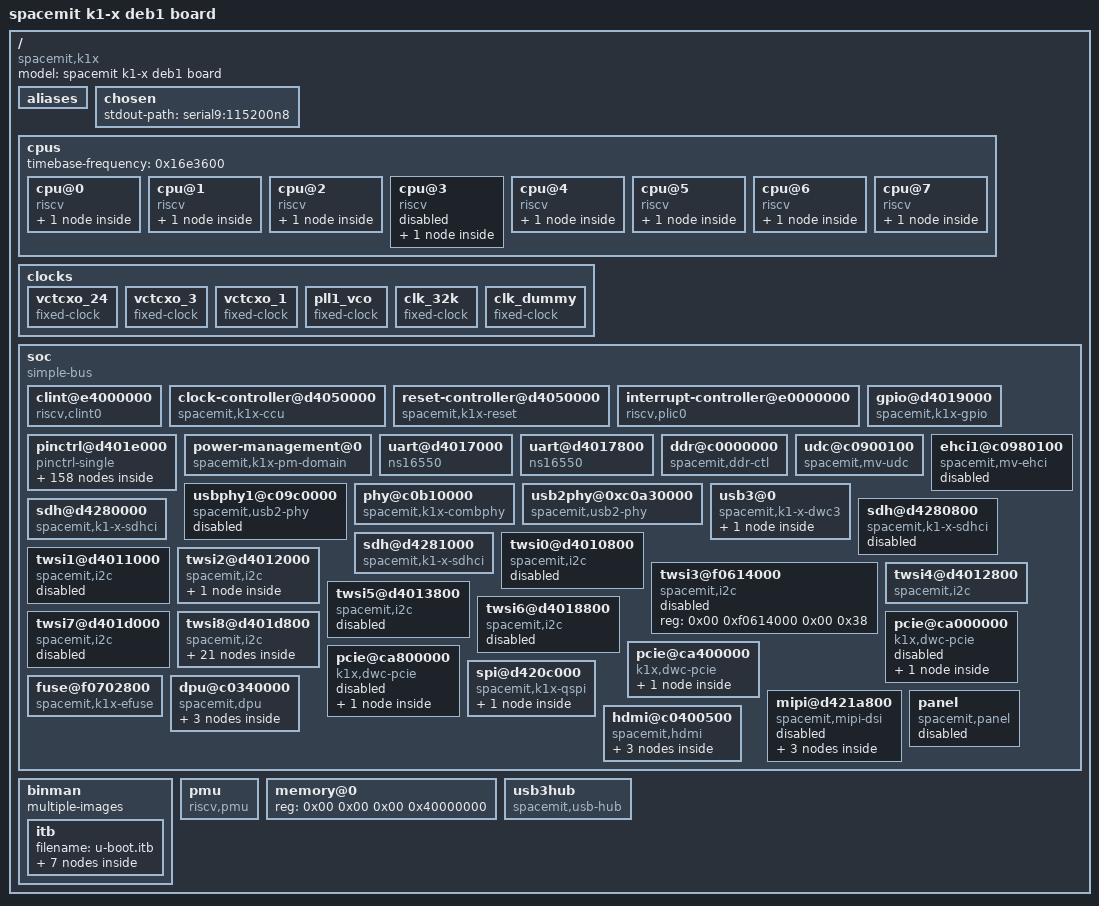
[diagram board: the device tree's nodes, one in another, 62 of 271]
/dts-v1/;

/ {
	compatible = "spacemit,k1x\0riscv";
	#address-cells = <0x02>;
	#size-cells = <0x02>;
	model = "spacemit k1-x deb1 board";

	aliases {
		serial0 = "/soc/uart@d4017000";
		serial9 = "/soc/uart@d4017800";
		mmc0 = "/soc/sdh@d4280000";
		mmc1 = "/soc/sdh@d4280800";
		mmc2 = "/soc/sdh@d4281000";
		efuse_power = "/soc/twsi8@d401d800/pmic@41/regulators/LDO_REG9";
	};

	chosen {
		stdout-path = "serial9:115200n8";
/*
		bootargs = "earlycon=sbi console=ttyS0,115200 debug loglevel=8,initcall_debug=1 rdinit=/init.tmp";
		stdout-path = "serial9:115200n8";

		opensbi-domains {
			compatible = "opensbi,domain,config";

			rpmsg_shmem {
				compatible = "opensbi,domain,memregion";
				base = <0x00 0x4e400000>;
				order = <0x16>;
				phandle = <0x02>;
			};

			rtcode {
				compatible = "opensbi,domain,memregion";
				base = <0x00 0x4e800000>;
				order = <0x17>;
				phandle = <0x03>;
			};

			rtheap {
				compatible = "opensbi,domain,memregion";
				base = <0x00 0x4f000000>;
				order = <0x18>;
				phandle = <0x04>;
			};

			allmem {
				compatible = "opensbi,domain,memregion";
				base = <0x00 0x00>;
				order = <0x40>;
				phandle = <0x05>;
			};

			t-domain {
				compatible = "opensbi,domain,instance";
				possible-harts = <0x01>;
				regions = <0x02 0x3f 0x03 0x3f 0x04 0x3f 0x05 0x3f>;
				boot-hart = <0x01>;
				next-arg1 = <0x00 0x42200000>;
				next-addr = <0x00 0x4e800000>;
				next-mode = <0x01>;
				phandle = <0x0e>;
			};

			u-domain {
				compatible = "opensbi,domain,instance";
				possible-harts = <0x06 0x07 0x08 0x09 0x0a 0x0b 0x0c>;
				regions = <0x02 0x3f 0x03 0x3f 0x04 0x3f 0x05 0x3f>;
				next-addr = <0x00 0x200000>;
				next-arg1 = <0x00 0x31b180>;
				boot-hart = <0x07>;
				system-reset-allowed;
				system-suspend-allowed;
				phandle = <0x0d>;
			};
		};
*/
	};

	cpus {
		#address-cells = <0x01>;
		#size-cells = <0x00>;
		timebase-frequency = <0x16e3600>;

		cpu@0 {
			compatible = "riscv";
			device_type = "cpu";
			reg = <0x00>;
			status = "okay";
			riscv,isa = "rv64imafdcvsu_zicsr_zifencei_zicbom_zihintpause_zba_zbb_zbc_zbs_svpbmt_sstc_sscofpmf";
			mmu-type = "riscv,sv39";
			opensbi-domain = <0x0d>;
			boot_freq_cluster0 = <0x12bce0>;
			boot_freq_cluster1 = <0x12bce0>;
			phandle = <0x06>;

			interrupt-controller {
				#interrupt-cells = <0x01>;
				compatible = "riscv,cpu-intc";
				interrupt-controller;
				phandle = <0x0f>;
			};
		};

		cpu@1 {
			compatible = "riscv";
			device_type = "cpu";
			reg = <0x01>;
			status = "okay";
			riscv,isa = "rv64imafdcvsu_zicsr_zifencei_zicbom_zihintpause_zba_zbb_zbc_zbs_svpbmt_sstc_sscofpmf";
			mmu-type = "riscv,sv39";
			opensbi-domain = <0x0d>;
			phandle = <0x07>;

			interrupt-controller {
				#interrupt-cells = <0x01>;
				compatible = "riscv,cpu-intc";
				interrupt-controller;
				phandle = <0x10>;
			};
		};

		cpu@2 {
			compatible = "riscv";
			device_type = "cpu";
			reg = <0x02>;
			status = "okay";
			riscv,isa = "rv64imafdcvsu_zicsr_zifencei_zicbom_zihintpause_zba_zbb_zbc_zbs_svpbmt_sstc_sscofpmf";
			mmu-type = "riscv,sv39";
			opensbi-domain = <0x0d>;
			phandle = <0x08>;

			interrupt-controller {
				#interrupt-cells = <0x01>;
				compatible = "riscv,cpu-intc";
				interrupt-controller;
				phandle = <0x11>;
			};
		};

		cpu@3 {
			compatible = "riscv";
			device_type = "cpu";
			reg = <0x03>;
			status = "disabled";
			riscv,isa = "rv64imafdcvsu_zicsr_zifencei_zicbom_zihintpause_zba_zbb_zbc_zbs_svpbmt_sstc_sscofpmf";
			mmu-type = "riscv,sv39";
			opensbi-domain = <0x0e>;
			phandle = <0x01>;

			interrupt-controller {
				#interrupt-cells = <0x01>;
				compatible = "riscv,cpu-intc";
				interrupt-controller;
				phandle = <0x12>;
			};
		};

		cpu@4 {
			compatible = "riscv";
			device_type = "cpu";
			reg = <0x04>;
			status = "okay";
			riscv,isa = "rv64imafdcvsu_zicsr_zifencei_zicbom_zihintpause_zba_zbb_zbc_zbs_svpbmt_sstc_sscofpmf";
			mmu-type = "riscv,sv39";
			opensbi-domain = <0x0d>;
			phandle = <0x09>;

			interrupt-controller {
				#interrupt-cells = <0x01>;
				compatible = "riscv,cpu-intc";
				interrupt-controller;
				phandle = <0x13>;
			};
		};

		cpu@5 {
			compatible = "riscv";
			device_type = "cpu";
			reg = <0x05>;
			status = "okay";
			riscv,isa = "rv64imafdcvsu_zicsr_zifencei_zicbom_zihintpause_zba_zbb_zbc_zbs_svpbmt_sstc_sscofpmf";
			mmu-type = "riscv,sv39";
			opensbi-domain = <0x0d>;
			phandle = <0x0a>;

			interrupt-controller {
				#interrupt-cells = <0x01>;
				compatible = "riscv,cpu-intc";
				interrupt-controller;
				phandle = <0x14>;
			};
		};

		cpu@6 {
			compatible = "riscv";
			device_type = "cpu";
			reg = <0x06>;
			status = "okay";
			riscv,isa = "rv64imafdcvsu_zicsr_zifencei_zicbom_zihintpause_zba_zbb_zbc_zbs_svpbmt_sstc_sscofpmf";
			mmu-type = "riscv,sv39";
			opensbi-domain = <0x0d>;
			phandle = <0x0b>;

			interrupt-controller {
				#interrupt-cells = <0x01>;
				compatible = "riscv,cpu-intc";
				interrupt-controller;
				phandle = <0x15>;
			};
		};

		cpu@7 {
			compatible = "riscv";
			device_type = "cpu";
			reg = <0x07>;
			status = "okay";
			riscv,isa = "rv64imafdcvsu_zicsr_zifencei_zicbom_zihintpause_zba_zbb_zbc_zbs_svpbmt_sstc_sscofpmf";
			mmu-type = "riscv,sv39";
			opensbi-domain = <0x0d>;
			phandle = <0x0c>;

			interrupt-controller {
				#interrupt-cells = <0x01>;
				compatible = "riscv,cpu-intc";
				interrupt-controller;
				phandle = <0x16>;
			};
		};
	};

	clocks {
		#address-cells = <0x02>;
		#size-cells = <0x02>;
		ranges;

		vctcxo_24 {
			#clock-cells = <0x00>;
			compatible = "fixed-clock";
			clock-frequency = <0x16e3600>;
			clock-output-names = "vctcxo_24";
			phandle = <0x17>;
		};

		vctcxo_3 {
			#clock-cells = <0x00>;
			compatible = "fixed-clock";
			clock-frequency = <0x2dc6c0>;
			clock-output-names = "vctcxo_3";
			phandle = <0x18>;
		};

		vctcxo_1 {
			#clock-cells = <0x00>;
			compatible = "fixed-clock";
			clock-frequency = <0xf4240>;
			clock-output-names = "vctcxo_1";
			phandle = <0x19>;
		};

		pll1_vco {
			#clock-cells = <0x00>;
			compatible = "fixed-clock";
			clock-frequency = <0x1770000>;
			clock-output-names = "pll1_vco";
			phandle = <0x1a>;
		};

		clk_32k {
			#clock-cells = <0x00>;
			compatible = "fixed-clock";
			clock-frequency = <0x7d00>;
			clock-output-names = "clk_32k";
			phandle = <0x1b>;
		};

		clk_dummy {
			#clock-cells = <0x00>;
			compatible = "fixed-clock";
			clock-frequency = <0x00>;
			clock-output-names = "clk_dummy";
			phandle = <0x1c>;
		};
	};

	soc {
		compatible = "simple-bus";
		#address-cells = <0x02>;
		#size-cells = <0x02>;
		ranges;

		clint@e4000000 {
			compatible = "riscv,clint0";
			interrupts-extended = <0x0f 0x03 0x0f 0x07 0x10 0x03 0x10 0x07 0x11 0x03 0x11 0x07 0x12 0x03 0x12 0x07 0x13 0x03 0x13 0x07 0x14 0x03 0x14 0x07 0x15 0x03 0x15 0x07 0x16 0x03 0x16 0x07>;
			reg = <0x00 0xe4000000 0x00 0x10000>;
		};

		clock-controller@d4050000 {
			compatible = "spacemit,k1x-ccu";
			reg = <0x00 0xd4050000 0x00 0x209c 0x00 0xd4282800 0x00 0x400 0x00 0xd4015000 0x00 0x1000 0x00 0xd4090000 0x00 0x1000 0x00 0xd4282c00 0x00 0x400 0x00 0xd8440000 0x00 0x98 0x00 0xc0000000 0x00 0x4280 0x00 0xf0610000 0x00 0x20>;
			reg-names = "mpmu\0apmu\0apbc\0apbs\0ciu\0dciu\0ddrc\0apbc2";
			clocks = <0x17 0x18 0x19 0x1a 0x1b 0x1c>;
			clock-names = "vctcxo_24\0vctcxo_3\0vctcxo_1\0pll1_vco\0clk_32k\0clk_dummy";
			#clock-cells = <0x01>;
			status = "okay";
			phandle = <0x1d>;
		};

		reset-controller@d4050000 {
			compatible = "spacemit,k1x-reset";
			reg = <0x00 0xd4050000 0x00 0x209c 0x00 0xd4282800 0x00 0x400 0x00 0xd4015000 0x00 0x1000 0x00 0xd4090000 0x00 0x1000 0x00 0xd4282c00 0x00 0x400 0x00 0xd8440000 0x00 0x98 0x00 0xc0000000 0x00 0x4280 0x00 0xf0610000 0x00 0x20>;
			reg-names = "mpmu\0apmu\0apbc\0apbs\0ciu\0dciu\0ddrc\0apbc2";
			#reset-cells = <0x01>;
			status = "okay";
			phandle = <0x21>;
		};

		interrupt-controller@e0000000 {
			#interrupt-cells = <0x01>;
			compatible = "riscv,plic0";
			interrupt-controller;
			interrupts-extended = <0x0f 0x0b 0x0f 0x09 0x10 0x0b 0x10 0x09 0x11 0x0b 0x11 0x09 0x12 0x0b 0x12 0x09 0x13 0x0b 0x13 0x09 0x14 0x0b 0x14 0x09 0x15 0x0b 0x15 0x09 0x16 0x0b 0x16 0x09>;
			reg = <0x00 0xe0000000 0x00 0x4000000>;
			reg-names = "control";
			riscv,max-priority = <0x07>;
			riscv,ndev = <0x9f>;
			phandle = <0x1e>;
		};

		gpio@d4019000 {
			compatible = "spacemit,k1x-gpio";
			reg = <0x00 0xd4019000 0x00 0x800>;
			gpio-controller;
			gpio-count = <0x80>;
			#gpio-cells = <0x02>;
			interrupts = <0x3a>;
			clocks = <0x1d 0x6c>;
			interrupt-names = "gpio_mux";
			interrupt-parent = <0x1e>;
			gpio-ranges = <0x1f 0x31 0x32 0x02 0x1f 0x3a 0x3b 0x01 0x1f 0x3f 0x40 0x05 0x1f 0x46 0x47 0x04 0x1f 0x4a 0x4b 0x01 0x1f 0x50 0x51 0x04 0x1f 0x5a 0x7f 0x03 0x1f 0x60 0x78 0x02 0x1f 0x6e 0x74 0x01 0x1f 0x72 0x86 0x03 0x1f 0x7b 0x8f 0x05>;
			phandle = <0x2a>;
		};

		pinctrl@d401e000 {
			compatible = "pinctrl-single";
			reg = <0x00 0xd401e000 0x00 0x400>;
			#address-cells = <0x01>;
			#size-cells = <0x01>;
			#pinctrl-cells = <0x02>;
			#gpio-range-cells = <0x03>;
			pinctrl-single,register-width = <0x20>;
			pinctrl-single,function-mask = <0xff77>;
			pinctrl-single,gpio-range = <0x20 0x32 0x02 0xc440 0x20 0x3b 0x01 0xb040 0x20 0x40 0x02 0xb040 0x20 0x42 0x01 0xd040 0x20 0x43 0x02 0xb040 0x20 0x47 0x02 0xd041 0x20 0x49 0x01 0xb041 0x20 0x4a 0x01 0xd041 0x20 0x4b 0x01 0xd040 0x20 0x51 0x01 0xc440 0x20 0x52 0x03 0xd040 0x20 0x7f 0x01 0xb040 0x20 0x80 0x02 0xd040 0x20 0x78 0x01 0xb041 0x20 0x79 0x01 0xa041 0x20 0x74 0x01 0xb040 0x20 0x86 0x01 0xb040 0x20 0x87 0x02 0xb040 0x20 0x8f 0x01 0xa040 0x20 0x90 0x01 0xd040 0x20 0x91 0x03 0xb040>;
			phandle = <0x1f>;

			gpio-range {
				#pinctrl-single,gpio-range-cells = <0x03>;
				phandle = <0x20>;
			};

			uart0_0_grp {
				pinctrl-single,pins = <0x1b8 0x03 0xc440 0x1bc 0x03 0xc440>;
			};

			uart0_1_grp {
				pinctrl-single,pins = <0x1c8 0x01 0xc440 0x144 0x03 0xa440>;
			};

			uart0_2_grp {
				pinctrl-single,pins = <0x114 0x02 0xb040 0x118 0x02 0xd040>;
			};

			uart2_grp {
				pinctrl-single,pins = <0x58 0x01 0xb040 0x5c 0x01 0xb040 0x60 0x01 0xb040 0x64 0x01 0xb040>;
			};

			uart3_0_grp {
				pinctrl-single,pins = <0x148 0x02 0xd040 0x14c 0x02 0xd040 0x150 0x02 0xd040 0x154 0x02 0xd040>;
			};

			uart3_1_grp {
				pinctrl-single,pins = <0x4c 0x02 0xd040 0x50 0x02 0xd040 0x54 0x02 0xd040 0x58 0x02 0xb040>;
			};

			uart3_2_grp {
				pinctrl-single,pins = <0xd8 0x04 0xb040 0xdc 0x04 0xd040 0xe0 0x04 0xd040 0xe4 0x04 0xd040>;
			};

			uart4_0_grp {
				pinctrl-single,pins = <0x16c 0x04 0xa440 0x168 0x04 0xa440>;
			};

			uart4_1_grp {
				pinctrl-single,pins = <0x148 0x03 0xd040 0x14c 0x03 0xd040 0x150 0x03 0xd040 0x154 0x03 0xd040>;
			};

			uart4_2_grp {
				pinctrl-single,pins = <0x60 0x02 0xb040 0x64 0x02 0xb040>;
			};

			uart4_3_grp {
				pinctrl-single,pins = <0x88 0x02 0xb040 0x8c 0x02 0xb040 0x90 0x02 0xb040 0x94 0x02 0xb040>;
			};

			uart4_4_grp {
				pinctrl-single,pins = <0x20c 0x04 0xb040 0x210 0x04 0xb040 0x214 0x04 0xb040 0x218 0x04 0xb040>;
			};

			uart5_0_grp {
				pinctrl-single,pins = <0x17c 0x03 0xa440 0x178 0x03 0xa440>;
			};

			uart5_1_grp {
				pinctrl-single,pins = <0x68 0x02 0xb040 0x6c 0x02 0xb040 0x70 0x02 0xb040 0x74 0x02 0xb040>;
			};

			uart5_2_grp {
				pinctrl-single,pins = <0xac 0x02 0xb040 0xb0 0x02 0xb040 0xb4 0x02 0xb040 0xb8 0x02 0xb040>;
			};

			uart5_3_grp {
				pinctrl-single,pins = <0x11c 0x04 0xd040 0x120 0x04 0xd040 0x124 0x04 0xb040 0x128 0x04 0xd040>;
			};

			uart6_0_grp {
				pinctrl-single,pins = <0x158 0x02 0xd040 0x1ec 0x02 0xd040 0x1f0 0x02 0xd040 0x1fc 0x02 0xb040>;
			};

			uart6_1_grp {
				pinctrl-single,pins = <0x04 0x02 0xb040 0x08 0x02 0xb040 0x0c 0x02 0xb040 0x10 0x02 0xb040>;
			};

			uart6_2_grp {
				pinctrl-single,pins = <0xe4 0x02 0xd040 0xe8 0x02 0xd040>;
			};

			uart7_0_grp {
				pinctrl-single,pins = <0x1f4 0x02 0xb040 0x1f8 0x02 0xb040>;
			};

			uart7_1_grp {
				pinctrl-single,pins = <0x14 0x02 0xb040 0x18 0x02 0xb040 0x1c 0x02 0xb040 0x20 0x02 0xb040>;
			};

			uart8_0_grp {
				pinctrl-single,pins = <0x14c 0x04 0xd040 0x150 0x04 0xd040>;
			};

			uart8_1_grp {
				pinctrl-single,pins = <0x24 0x02 0xb040 0x28 0x02 0xb040 0x2c 0x02 0xb040 0x30 0x02 0xb040>;
			};

			uart8_2_grp {
				pinctrl-single,pins = <0x130 0x04 0xc440 0x134 0x04 0xc440 0x138 0x04 0xc440 0x13c 0x04 0xc440>;
			};

			uart9_0_grp {
				pinctrl-single,pins = <0x34 0x02 0xb040 0x38 0x02 0xb040>;
			};

			uart9_1_grp {
				pinctrl-single,pins = <0x1d0 0x03 0xb040 0x21c 0x03 0xb040 0x220 0x03 0xb040 0x224 0x03 0xb040>;
			};

			uart9_2_grp {
				pinctrl-single,pins = <0x124 0x02 0xb040 0x128 0x02 0xd040>;
			};

			i2c0_grp {
				pinctrl-single,pins = <0xdc 0x01 0xc040 0xe0 0x01 0xc040>;
			};

			i2c1_grp {
				pinctrl-single,pins = <0xe4 0x01 0xc040 0xe8 0x01 0xc040>;
			};

			i2c2_0_grp {
				pinctrl-single,pins = <0x154 0x04 0xc040 0x158 0x04 0xc040>;
				phandle = <0x2b>;
			};

			i2c2_1_grp {
				pinctrl-single,pins = <0x11c 0x02 0xc040 0x120 0x02 0xc040>;
			};

			i2c2_2_grp {
				pinctrl-single,pins = <0x114 0x03 0xc040 0x118 0x03 0xc040>;
			};

			i2c3_0_grp {
				pinctrl-single,pins = <0x9c 0x02 0xc040 0xa0 0x02 0xc040>;
			};

			i2c3_1_grp {
				pinctrl-single,pins = <0xc0 0x04 0xc040 0xc4 0x04 0xc040>;
			};

			i2c3_2_grp {
				pinctrl-single,pins = <0x138 0x03 0xc040 0x13c 0x03 0xc040>;
			};

			i2c4_0_grp {
				pinctrl-single,pins = <0xa4 0x02 0xc040 0xa8 0x02 0xc040>;
			};

			i2c4_1_grp {
				pinctrl-single,pins = <0x130 0x05 0xc040 0x134 0x05 0xc040>;
			};

			i2c4_2_grp {
				pinctrl-single,pins = <0xd0 0x04 0xc040 0xd4 0x04 0xc040>;
			};

			i2c5_0_grp {
				pinctrl-single,pins = <0x148 0x05 0xc040 0x14c 0x05 0xc040>;
			};

			i2c5_1_grp {
				pinctrl-single,pins = <0xdc 0x05 0xc040 0xe0 0x05 0xc040>;
			};

			i2c6_0_grp {
				pinctrl-single,pins = <0x150 0x05 0xc040 0x1fc 0x05 0xa040>;
			};

			i2c6_1_grp {
				pinctrl-single,pins = <0x228 0x02 0xc040 0x22c 0x02 0xc040>;
			};

			i2c6_2_grp {
				pinctrl-single,pins = <0xe4 0x02 0xc040 0xe8 0x02 0xc040>;
			};

			i2c7_grp {
				pinctrl-single,pins = <0x228 0x01 0xc040 0x22c 0x01 0xa040>;
			};

			i2c8_grp {
				pinctrl-single,pins = <0x1d4 0x00 0xc040 0x1d8 0x00 0xc040>;
			};

			one_wire_0_grp {
				pinctrl-single,pins = <0x1d0 0x05 0xb040>;
			};

			one_wire_1_grp {
				pinctrl-single,pins = <0xc0 0x05 0xa440>;
			};

			ir_rx_0_grp {
				pinctrl-single,pins = <0x1e4 0x02 0xb040>;
			};

			ir_rx_1_grp {
				pinctrl-single,pins = <0x140 0x01 0xa440>;
			};

			ir_rx_2_grp {
				pinctrl-single,pins = <0xec 0x04 0xb040>;
			};

			pwm0_0_grp {
				pinctrl-single,pins = <0x1b8 0x05 0xc440>;
			};

			pwm0_1_grp {
				pinctrl-single,pins = <0x3c 0x03 0xb040>;
			};

			pwm0_2_grp {
				pinctrl-single,pins = <0x5c 0x04 0xb040>;
			};

			pwm1_0_grp {
				pinctrl-single,pins = <0x1bc 0x05 0xc440>;
			};

			pwm1_1_grp {
				pinctrl-single,pins = <0x78 0x03 0xb040>;
			};

			pwm1_2_grp {
				pinctrl-single,pins = <0x60 0x04 0xb040>;
			};

			pwm2_0_grp {
				pinctrl-single,pins = <0x1c0 0x05 0xc440>;
			};

			pwm2_1_grp {
				pinctrl-single,pins = <0x5c 0x02 0xb040>;
			};

			pwm2_2_grp {
				pinctrl-single,pins = <0x7c 0x03 0xb040>;
			};

			pwm2_3_grp {
				pinctrl-single,pins = <0x64 0x04 0xb040>;
			};

			pwm3_0_grp {
				pinctrl-single,pins = <0x1c4 0x05 0xc440>;
			};

			pwm3_1_grp {
				pinctrl-single,pins = <0x88 0x03 0xb040>;
			};

			pwm3_2_grp {
				pinctrl-single,pins = <0x68 0x04 0xb040>;
			};

			pwm4_0_grp {
				pinctrl-single,pins = <0x1c8 0x05 0xc440>;
			};

			pwm4_1_grp {
				pinctrl-single,pins = <0x8c 0x03 0xb040>;
			};

			pwm5_0_grp {
				pinctrl-single,pins = <0x1cc 0x05 0xc440>;
			};

			pwm5_1_grp {
				pinctrl-single,pins = <0x90 0x03 0xb040>;
			};

			pwm6_0_grp {
				pinctrl-single,pins = <0x1f4 0x04 0xb040>;
			};

			pwm6_1_grp {
				pinctrl-single,pins = <0x94 0x03 0xb040>;
			};

			pwm7_0_grp {
				pinctrl-single,pins = <0x204 0x02 0xd040>;
			};

			pwm7_1_grp {
				pinctrl-single,pins = <0x98 0x02 0xb040>;
			};

			pwm8_0_grp {
				pinctrl-single,pins = <0x04 0x03 0xb040>;
			};

			pwm8_1_grp {
				pinctrl-single,pins = <0x9c 0x04 0xd040>;
			};

			pwm9_0_grp {
				pinctrl-single,pins = <0x08 0x03 0xb040>;
			};

			pwm9_1_grp {
				pinctrl-single,pins = <0xa0 0x04 0xd040>;
			};

			pwm9_2_grp {
				pinctrl-single,pins = <0x12c 0x02 0xd040>;
			};

			pwm10_0_grp {
				pinctrl-single,pins = <0x0c 0x03 0xb040>;
			};

			pwm10_1_grp {
				pinctrl-single,pins = <0xa4 0x04 0xd040>;
			};

			pwm11_0_grp {
				pinctrl-single,pins = <0x10 0x03 0xb040>;
			};

			pwm11_1_grp {
				pinctrl-single,pins = <0xa8 0x04 0xd040>;
			};

			pwm12_0_grp {
				pinctrl-single,pins = <0x14 0x03 0xb040>;
			};

			pwm12_1_grp {
				pinctrl-single,pins = <0xac 0x04 0xb040>;
			};

			pwm13_0_grp {
				pinctrl-single,pins = <0x18 0x03 0xb040>;
			};

			pwm13_1_grp {
				pinctrl-single,pins = <0xb0 0x04 0xb040>;
			};

			pwm14_0_grp {
				pinctrl-single,pins = <0x1c 0x03 0xb040>;
			};

			pwm14_1_grp {
				pinctrl-single,pins = <0xb4 0x04 0xb040>;
			};

			pwm15_0_grp {
				pinctrl-single,pins = <0x20 0x03 0xb040>;
			};

			pwm15_1_grp {
				pinctrl-single,pins = <0xb8 0x04 0xb040>;
			};

			pwm16_0_grp {
				pinctrl-single,pins = <0x28 0x03 0xb040>;
			};

			pwm16_1_grp {
				pinctrl-single,pins = <0xbc 0x04 0xb040>;
			};

			pwm17_0_grp {
				pinctrl-single,pins = <0x2c 0x03 0xb040>;
			};

			pwm17_1_grp {
				pinctrl-single,pins = <0xd8 0x02 0xb040>;
			};

			pwm18_0_grp {
				pinctrl-single,pins = <0x30 0x03 0xb040>;
			};

			pwm18_1_grp {
				pinctrl-single,pins = <0xe8 0x04 0xd040>;
			};

			pwm19_0_grp {
				pinctrl-single,pins = <0x38 0x03 0xb040>;
			};

			pwm19_1_grp {
				pinctrl-single,pins = <0x100 0x04 0xb040>;
			};

			sspa0_0_grp {
				pinctrl-single,pins = <0x228 0x03 0xd040 0x22c 0x03 0xd040 0x230 0x03 0xb040 0x234 0x03 0xb040 0x238 0x03 0xb040>;
			};

			sspa0_1_grp {
				pinctrl-single,pins = <0xec 0x02 0xb040 0x20c 0x02 0xb040 0x210 0x02 0xb040 0x214 0x02 0xb040 0x218 0x02 0xb040>;
			};

			sspa1_grp {
				pinctrl-single,pins = <0x64 0x03 0xb040 0x68 0x01 0xb040 0x6c 0x01 0xb040 0x70 0x01 0xb040 0x74 0x01 0xb040>;
			};

			ssp2_0_grp {
				pinctrl-single,pins = <0x130 0x01 0xc440 0x134 0x01 0xc440 0x138 0x01 0xc440 0x13c 0x01 0xc440>;
			};

			ssp2_1_grp {
				pinctrl-single,pins = <0x104 0x03 0xc440 0x108 0x03 0xc440 0x10c 0x03 0xc440 0x110 0x03 0xc440>;
			};

			ssp3_0_grp {
				pinctrl-single,pins = <0x130 0x02 0xc440 0x134 0x02 0xc440 0x138 0x02 0xc440 0x13c 0x02 0xc440>;
			};

			ssp3_1_grp {
				pinctrl-single,pins = <0xf0 0x02 0xd040 0xf4 0x02 0xd040 0xf8 0x02 0xd040 0xfc 0x02 0xd040>;
			};

			qspi_grp {
				pinctrl-single,pins = <0x174 0x00 0xa440 0x170 0x00 0xa440 0x16c 0x00 0xa440 0x168 0x00 0xa440 0x17c 0x00 0xa440 0x178 0x00 0xc440>;
				phandle = <0x30>;
			};

			mmc1_grp {
				pinctrl-single,pins = <0x1b8 0x00 0xc440 0x1bc 0x00 0xc440 0x1c0 0x00 0xc440 0x1c4 0x00 0xc440 0x1c8 0x00 0xc440 0x1cc 0x00 0xa440>;
				phandle = <0x28>;
			};

			mmc1_fast_grp {
				pinctrl-single,pins = <0x1b8 0x00 0xd840 0x1bc 0x00 0xd840 0x1c0 0x00 0xd840 0x1c4 0x00 0xd840 0x1c8 0x00 0xd840 0x1cc 0x00 0xb840>;
			};

			mmc2_grp {
				pinctrl-single,pins = <0x40 0x01 0xd040 0x44 0x01 0xd040 0x48 0x01 0xd040 0x4c 0x01 0xd040 0x50 0x01 0xd040 0x54 0x01 0xd040>;
			};

			usb0_0_grp {
				pinctrl-single,pins = <0x244 0x01 0xb040 0x248 0x01 0xb040 0x24c 0x01 0xb040>;
			};

			usb0_1_grp {
				pinctrl-single,pins = <0x104 0x01 0xb040 0x108 0x01 0xd040 0x100 0x01 0xb040>;
			};

			usb1_0_grp {
				pinctrl-single,pins = <0x240 0x01 0xb040>;
			};

			usb1_1_grp {
				pinctrl-single,pins = <0x10c 0x01 0xb040>;
			};

			usb2_0_grp {
				pinctrl-single,pins = <0x234 0x02 0xb040 0x238 0x02 0xb040 0x23c 0x01 0xb040>;
			};

			usb2_1_grp {
				pinctrl-single,pins = <0x114 0x01 0xb040 0x118 0x01 0xd040 0x110 0x01 0xb040>;
			};

			pcie0_0_grp {
				pinctrl-single,pins = <0x40 0x02 0xd040 0x44 0x02 0xd040 0x48 0x02 0xd040>;
			};

			pcie0_1_grp {
				pinctrl-single,pins = <0x78 0x04 0xb040 0x7c 0x04 0xb040 0x80 0x04 0xb040>;
			};

			pcie0_2_grp {
				pinctrl-single,pins = <0x1d0 0x04 0xb040 0x21c 0x04 0xb040 0x220 0x04 0xb040>;
			};

			pcie0_3_grp {
				pinctrl-single,pins = <0xd8 0x03 0xb040 0xdc 0x03 0xd040 0xe0 0x03 0xd040>;
			};

			pcie1_0_grp {
				pinctrl-single,pins = <0x40 0x04 0x1040 0x44 0x04 0x1040 0x48 0x04 0x1040>;
			};

			pcie1_1_grp {
				pinctrl-single,pins = <0x84 0x04 0xb040 0x88 0x04 0xb040 0x8c 0x04 0xb040>;
			};

			pcie1_2_grp {
				pinctrl-single,pins = <0xe4 0x03 0xd040 0xe8 0x03 0xd040 0xec 0x03 0xb040>;
			};

			pcie1_3_grp {
				pinctrl-single,pins = <0xf0 0x04 0xd040 0xf4 0x04 0xd040 0xf8 0x04 0xd040>;
				phandle = <0x2e>;
			};

			pcie2_0_grp {
				pinctrl-single,pins = <0x4c 0x04 0xd040 0x50 0x04 0xd040 0x54 0x04 0xd040>;
			};

			pcie2_1_grp {
				pinctrl-single,pins = <0x90 0x04 0xb040 0x94 0x04 0xb040 0x98 0x04 0xb040>;
			};

			pcie2_2_grp {
				pinctrl-single,pins = <0xfc 0x04 0xd040 0x12c 0x04 0xd040 0x224 0x04 0xb040>;
			};

			pcie2_3_grp {
				pinctrl-single,pins = <0x20c 0x03 0xb040 0x210 0x03 0xb040 0x214 0x03 0xb040>;
			};

			pcie2_4_grp {
				pinctrl-single,pins = <0xfc 0x04 0xd040 0x210 0x03 0xd040 0x224 0x04 0xb040>;
			};

			gmac0_grp {
				pinctrl-single,pins = <0x04 0x01 0x1040 0x08 0x01 0x1040 0x0c 0x01 0x1040 0x10 0x01 0x1040 0x14 0x01 0x1040 0x18 0x01 0x1040 0x1c 0x01 0x1040 0x20 0x01 0x1040 0x24 0x01 0x1040 0x28 0x01 0x1040 0x2c 0x01 0x1040 0x30 0x01 0x1040 0x34 0x01 0x1040 0x38 0x01 0x1040 0x3c 0x01 0x1040 0xb8 0x01 0x1040>;
				phandle = <0x22>;
			};

			gmac1_grp {
				pinctrl-single,pins = <0x78 0x01 0x1040 0x7c 0x01 0x1040 0x80 0x01 0x1040 0x84 0x01 0x1040 0x88 0x01 0x1040 0x8c 0x01 0x1040 0x90 0x01 0x1040 0x94 0x01 0x1040 0x98 0x01 0x1040 0x9c 0x01 0x1040 0xa0 0x01 0x1040 0xa4 0x01 0x1040 0xa8 0x01 0x1040 0xac 0x01 0x1040 0xb0 0x01 0x1040 0xbc 0x01 0x1040>;
			};

			can_0_grp {
				pinctrl-single,pins = <0x130 0x03 0xc440 0x134 0x03 0xc440>;
			};

			can_1_grp {
				pinctrl-single,pins = <0xdc 0x02 0xd040 0xe0 0x02 0xd040>;
			};

			hdmi_0_grp {
				pinctrl-single,pins = <0x1ec 0x01 0xd040 0x1f0 0x01 0xd040 0x1f4 0x01 0xb040 0x1f8 0x01 0xb040>;
				phandle = <0x35>;
			};

			hdmi_1_grp {
				pinctrl-single,pins = <0xf0 0x01 0xd040 0xf4 0x01 0xd040 0xf8 0x01 0xd040 0xfc 0x01 0xd040>;
			};

			spi_lcd_0_grp {
				pinctrl-single,pins = <0x1ec 0x03 0xd040 0x1f0 0x03 0xd040 0x1f4 0x03 0xb040 0x1f8 0x03 0xb040 0x1fc 0x03 0xb040 0x200 0x03 0xd040 0x204 0x03 0xd040>;
			};

			spi_lcd_1_grp {
				pinctrl-single,pins = <0x11c 0x03 0xd040 0x120 0x03 0xd040 0x124 0x03 0xb040 0x128 0x03 0xd040 0x12c 0x03 0xd040 0x218 0x03 0xb040 0x100 0x03 0xb040>;
			};

			camera0_grp {
				pinctrl-single,pins = <0xd8 0x01 0xb040>;
			};

			camera1_grp {
				pinctrl-single,pins = <0xec 0x01 0xb040>;
			};

			camera2_grp {
				pinctrl-single,pins = <0x230 0x01 0xb040>;
			};

			pmic_grp {
				pinctrl-single,pins = <0x1dc 0x00 0xd040 0x1e0 0x00 0xb040 0x1e4 0x00 0xb040>;
			};

			mn_clk_0_grp {
				pinctrl-single,pins = <0x204 0x01 0xd040>;
			};

			mn_clk_1_grp {
				pinctrl-single,pins = <0x148 0x04 0xd040>;
			};

			mn_clk_2_grp {
				pinctrl-single,pins = <0xb4 0x01 0xb040>;
			};

			mn_clk_3_grp {
				pinctrl-single,pins = <0x54 0x03 0xd040>;
			};

			mn_clk_4_grp {
				pinctrl-single,pins = <0x60 0x03 0xb040>;
			};

			mn_clk_5_grp {
				pinctrl-single,pins = <0x84 0x03 0xb040>;
			};

			mn_clk2_0_grp {
				pinctrl-single,pins = <0x200 0x01 0xd040>;
			};

			mn_clk2_1_grp {
				pinctrl-single,pins = <0x158 0x03 0xd040>;
			};

			vcxo_0_grp {
				pinctrl-single,pins = <0x1e0 0x03 0xb040 0x1e4 0x03 0xb040>;
			};

			vcxo_1_grp {
				pinctrl-single,pins = <0x44 0x03 0xd040 0x48 0x03 0xd040>;
			};

			vcxo_2_grp {
				pinctrl-single,pins = <0x1f8 0x04 0xb040 0x1fc 0x04 0xb040>;
			};

			vcxo_out_0_grp {
				pinctrl-single,pins = <0x200 0x02 0xd040>;
			};

			vcxo_out_1_grp {
				pinctrl-single,pins = <0x34 0x03 0xb040>;
			};

			32k_out_0_grp {
				pinctrl-single,pins = <0x58 0x03 0xb040>;
			};

			32k_out_1_grp {
				pinctrl-single,pins = <0x80 0x03 0xb040>;
			};

			32k_out_2_grp {
				pinctrl-single,pins = <0x74 0x04 0xb040>;
			};

			pri_grp {
				pinctrl-single,pins = <0x11c 0x00 0xd040 0x120 0x00 0xd040 0x124 0x00 0xb040 0x128 0x00 0xd040>;
			};

			usbp1_vbus {
				pinctrl-single,pins = <0x10c 0x00 0xd040>;
			};

			gpio80_pmx_func0 {
				pinctrl-single,pins = <0x144 0x00 0xc430>;
				phandle = <0x29>;
			};
		};

		power-management@0 {
			compatible = "spacemit,k1x-pm-domain";
			reg = <0x00 0xd4050000 0x00 0x3004 0x00 0xd4282800 0x00 0x400>;
			#power-domain-cells = <0x01>;
			phandle = <0x33>;
		};

		uart@d4017000 {
			compatible = "ns16550";
			reg = <0x00 0xd4017000 0x00 0x100>;
			reg-shift = <0x02>;
			reg-io-width = <0x04>;
			clock-frequency = <0xd59f80>;
			status = "okay";
		};

		uart@d4017800 {
			compatible = "ns16550";
			reg = <0x00 0xd4017800 0x00 0x100>;
			reg-shift = <0x02>;
			reg-io-width = <0x04>;
			clock-frequency = <0xd59f80>;
		};

		ddr@c0000000 {
			compatible = "spacemit,ddr-ctl";
			reg = <0x00 0xc0000000 0x00 0x400000>;
			datarate = <0x960>;
		};
/*
		ethernet@cac80000 {
			compatible = "spacemit,k1x-emac";
			reg = <0x00 0xcac80000 0x00 0x420>;
			ctrl-reg = <0x3e4>;
			dline-reg = <0x3e8>;
			clocks = <0x1d 0xce>;
			clock-names = "emac-clk";
			resets = <0x21 0x5c>;
			reset-names = "emac-reset";
			status = "okay";
			pinctrl-names = "default";
			pinctrl-0 = <0x22>;
			phy-reset-pin = <0x6e>;
			clk_tuning_enable;
			clk-tuning-by-delayline;
			tx-phase = <0x5a>;
			rx-phase = <0x49>;
			phy-mode = "rgmii";
			phy-addr = <0x01>;
			phy-handle = <0x23>;
			ref-clock-from-phy;

			mdio {
				#address-cells = <0x01>;
				#size-cells = <0x00>;

				phy@0 {
					compatible = "ethernet-phy-id001c.c916";
					device_type = "ethernet-phy";
					reg = <0x01>;
					phandle = <0x23>;
				};
			};
		};
*/
		udc@c0900100 {
			compatible = "spacemit,mv-udc";
			reg = <0x00 0xc0900100 0x00 0x4000>;
			interrupts = <0x69>;
			interrupt-parent = <0x1e>;
			status = "okay";
		};

		usbphy1@c09c0000 {
			compatible = "spacemit,usb2-phy";
			reg = <0x00 0xc09c0000 0x00 0x200>;
			spacemit,phy-name = "mv-usb-phy";
			spacemit,pll-lock-bypass;
			clocks = <0x1d 0xb5>;
			#phy-cells = <0x00>;
			status = "disabled";
			phandle = <0x24>;
		};

		ehci1@c0980100 {
			compatible = "spacemit,mv-ehci";
			reg = <0x00 0xc0980100 0x00 0x4000>;
			interrupts = <0x76>;
			interrupt-parent = <0x1e>;
			spacemit,ehci-name = "mv-ehci";
			spacemit,otg-force-a-bus-req;
			resets = <0x21 0x4b>;
			clocks = <0x1d 0xb5>;
			phys = <0x24>;
			status = "disabled";
		};

		phy@c0b10000 {
			compatible = "spacemit,k1x-combphy";
			reg = <0x00 0xc0b10000 0x00 0x800 0x00 0xd4282910 0x00 0x400>;
			reg-names = "puphy\0phy_sel";
			resets = <0x21 0x59>;
			reset-names = "phy_rst";
			#phy-cells = <0x01>;
			status = "okay";
			phandle = <0x26>;
		};

		usb2phy@0xc0a30000 {
			compatible = "spacemit,usb2-phy";
			reg = <0x00 0xc0a30000 0x00 0x200>;
			spacemit,phy-name = "mv-usb-phy";
			spacemit,pll-lock-bypass;
			clocks = <0x1d 0xb7>;
			#phy-cells = <0x00>;
			status = "okay";
			phandle = <0x27>;
		};

		usb3@0 {
			compatible = "spacemit,k1-x-dwc3";
			#address-cells = <0x02>;
			#size-cells = <0x02>;
			resets = <0x21 0x4c>;
			reset-names = "ctl_rst";
			clocks = <0x1d 0xb7>;
			clock-names = "usbdrd30";
			interrupt-parent = <0x1e>;
			interrupts = <0x95>;
			ranges;
			status = "okay";
			vbus-supply = <0x25>;

			dwc3@c0a00000 {
				compatible = "snps,dwc3";
				reg = <0x00 0xc0a00000 0x00 0x10000>;
				interrupt-parent = <0x1e>;
				interrupts = <0x7d>;
				phys = <0x26 0x04 0x27>;
				phy-names = "usb3-phy\0usb2-phy";
				dr_mode = "host";
				phy_type = "utmi";
				snps,dis_enblslpm_quirk;
				snps,dis-u2-freeclk-exists-quirk;
				snps,dis-del-phy-power-chg-quirk;
				snps,dis_u2_susphy_quirk;
				snps,dis_u3_susphy_quirk;
			};
		};

		sdh@d4280000 {
			compatible = "spacemit,k1-x-sdhci";
			reg = <0x00 0xd4280000 0x00 0x200>;
			interrupt-parent = <0x1e>;
			interrupts = <0x63>;
			resets = <0x21 0x47 0x21 0x48>;
			reset-names = "sdh_axi\0sdh0";
			clocks = <0x1d 0xb2 0x1d 0xb1>;
			clock-names = "sdh-io\0sdh-core";
			status = "okay";
			pinctrl-names = "default";
			pinctrl-0 = <0x28 0x29>;
			bus-width = <0x04>;
			cd-gpios = <0x2a 0x50 0x00>;
			cd-inverted;
			cap-sd-highspeed;
			sdh-phy-module = <0x00>;
			clk-src-freq = <0xc350000>;
		};

		sdh@d4280800 {
			compatible = "spacemit,k1-x-sdhci";
			reg = <0x00 0xd4280800 0x00 0x200>;
			interrupt-parent = <0x1e>;
			interrupts = <0x64>;
			resets = <0x21 0x47 0x21 0x49>;
			reset-names = "sdh_axi\0sdh1";
			clocks = <0x1d 0xb3 0x1d 0xb1>;
			clock-names = "sdh-io\0sdh-core";
			status = "disabled";
		};

		sdh@d4281000 {
			compatible = "spacemit,k1-x-sdhci";
			reg = <0x00 0xd4281000 0x00 0x200>;
			interrupt-parent = <0x1e>;
			interrupts = <0x65>;
			resets = <0x21 0x47 0x21 0x53>;
			reset-names = "sdh_axi\0sdh2";
			clocks = <0x1d 0xb4 0x1d 0xb1>;
			clock-names = "sdh-io\0sdh-core";
			status = "okay";
			bus-width = <0x08>;
			non-removable;
			mmc-hs400-1_8v;
			mmc-hs400-enhanced-strobe;
			sdh-phy-module = <0x01>;
			clk-src-freq = <0x165a0bc0>;
		};

		twsi0@d4010800 {
			compatible = "spacemit,i2c";
			reg = <0x00 0xd4010800 0x00 0x38>;
			clocks = <0x1d 0x83>;
			resets = <0x21 0x1b>;
			#address-cells = <0x01>;
			#size-cells = <0x00>;
			status = "disabled";
		};

		twsi1@d4011000 {
			compatible = "spacemit,i2c";
			reg = <0x00 0xd4011000 0x00 0x38>;
			clocks = <0x1d 0x84>;
			resets = <0x21 0x24>;
			#address-cells = <0x01>;
			#size-cells = <0x00>;
			status = "disabled";
		};

		twsi2@d4012000 {
			compatible = "spacemit,i2c";
			reg = <0x00 0xd4012000 0x00 0x38>;
			clocks = <0x1d 0x85>;
			resets = <0x21 0x26>;
			#address-cells = <0x01>;
			#size-cells = <0x00>;
			status = "okay";
			pinctrl-names = "default";
			pinctrl-0 = <0x2b>;

			eeprom@50 {
				compatible = "atmel,24c02";
				reg = <0x50>;
				vin-supply-names = "eeprom_1v8";
				status = "okay";
			};
		};

		twsi3@f0614000 {
			compatible = "spacemit,i2c";
			reg = <0x00 0xf0614000 0x00 0x38>;
			#address-cells = <0x01>;
			#size-cells = <0x00>;
			status = "disabled";
		};

		twsi4@d4012800 {
			compatible = "spacemit,i2c";
			reg = <0x00 0xd4012800 0x00 0x38>;
			clocks = <0x1d 0x86>;
			resets = <0x21 0x27>;
			#address-cells = <0x01>;
			#size-cells = <0x00>;
			status = "okay";
			clock-frequency = <0x61a80>;
		};

		twsi5@d4013800 {
			compatible = "spacemit,i2c";
			reg = <0x00 0xd4013800 0x00 0x38>;
			clocks = <0x1d 0x87>;
			resets = <0x21 0x28>;
			#address-cells = <0x01>;
			#size-cells = <0x00>;
			status = "disabled";
		};

		twsi6@d4018800 {
			compatible = "spacemit,i2c";
			reg = <0x00 0xd4018800 0x00 0x38>;
			clocks = <0x1d 0x88>;
			resets = <0x21 0x29>;
			#address-cells = <0x01>;
			#size-cells = <0x00>;
			status = "disabled";
		};

		twsi7@d401d000 {
			compatible = "spacemit,i2c";
			reg = <0x00 0xd401d000 0x00 0x38>;
			clocks = <0x1d 0x89>;
			resets = <0x21 0x2a>;
			#address-cells = <0x01>;
			#size-cells = <0x00>;
			status = "disabled";
		};

		twsi8@d401d800 {
			compatible = "spacemit,i2c";
			reg = <0x00 0xd401d800 0x00 0x38>;
			clocks = <0x1d 0x8a>;
			resets = <0x21 0x2b>;
			#address-cells = <0x01>;
			#size-cells = <0x00>;
			status = "okay";
			clock-frequency = <0x186a0>;
			u-boot,dm-spl;

			pmic@41 {
				compatible = "spacemit,spm8821";
				reg = <0x41>;
				bus = <0x08>;
				u-boot,dm-spl;

				regulators {

					DCDC_REG1 {
						regulator-name = "dcdc1";
						regulator-min-microvolt = <0x7a120>;
						regulator-max-microvolt = <0x34a490>;
						regulator-init-microvolt = <0xe7ef0>;
						regulator-boot-on;
						u-boot,dm-spl;

						regulator-state-mem {
							regulator-off-in-suspend;
						};
					};

					DCDC_REG2 {
						regulator-name = "dcdc2";
						regulator-min-microvolt = <0x7a120>;
						regulator-max-microvolt = <0x34a490>;
					};

					DCDC_REG3 {
						regulator-name = "dcdc3";
						regulator-min-microvolt = <0x7a120>;
						regulator-max-microvolt = <0x34a490>;
						regulator-boot-on;
						u-boot,dm-spl;
					};

					DCDC_REG4 {
						regulator-name = "dcdc4";
						regulator-min-microvolt = <0x7a120>;
						regulator-max-microvolt = <0x34a490>;
					};

					DCDC_REG5 {
						regulator-name = "dcdc5";
						regulator-min-microvolt = <0x7a120>;
						regulator-max-microvolt = <0x34a490>;
					};

					DCDC_REG6 {
						regulator-name = "dcdc6";
						regulator-min-microvolt = <0x7a120>;
						regulator-max-microvolt = <0x34a490>;
					};

					LDO_REG1 {
						regulator-name = "ldo1";
						regulator-min-microvolt = <0x7a120>;
						regulator-max-microvolt = <0x33e140>;
						regulator-init-microvolt = <0x325aa0>;
						regulator-boot-on;
						u-boot,dm-spl;
					};

					LDO_REG2 {
						regulator-name = "ldo2";
						regulator-min-microvolt = <0x7a120>;
						regulator-max-microvolt = <0x33e140>;
					};

					LDO_REG3 {
						regulator-name = "ldo3";
						regulator-min-microvolt = <0x7a120>;
						regulator-max-microvolt = <0x33e140>;
					};

					LDO_REG4 {
						regulator-name = "ldo4";
						regulator-min-microvolt = <0x7a120>;
						regulator-max-microvolt = <0x33e140>;
					};

					LDO_REG5 {
						regulator-name = "ldo5";
						regulator-min-microvolt = <0x7a120>;
						regulator-max-microvolt = <0x33e140>;
					};

					LDO_REG6 {
						regulator-name = "ldo6";
						regulator-min-microvolt = <0x7a120>;
						regulator-max-microvolt = <0x33e140>;
					};

					LDO_REG7 {
						regulator-name = "ldo7";
						regulator-min-microvolt = <0x7a120>;
						regulator-max-microvolt = <0x33e140>;
					};

					LDO_REG8 {
						regulator-name = "ldo8";
						regulator-min-microvolt = <0x7a120>;
						regulator-max-microvolt = <0x33e140>;
					};

					LDO_REG9 {
						regulator-name = "ldo9";
						regulator-min-microvolt = <0x7a120>;
						regulator-max-microvolt = <0x33e140>;
					};

					LDO_REG10 {
						regulator-name = "ldo10";
						regulator-min-microvolt = <0x7a120>;
						regulator-max-microvolt = <0x33e140>;
					};

					LDO_REG11 {
						regulator-name = "ldo11";
						regulator-min-microvolt = <0x7a120>;
						regulator-max-microvolt = <0x33e140>;
					};

					SWITCH_REG1 {
						regulator-name = "switch1";
					};
				};
			};
		};

		pcie@ca000000 {
			compatible = "k1x,dwc-pcie";
			reg = <0x00 0xca000000 0x00 0x1000 0x00 0xca300000 0x00 0x1ff24 0x00 0x80000000 0x00 0x100000 0x00 0xd4282bcc 0x00 0x08 0x00 0xc0b20000 0x00 0x1000 0x00 0xc0b10000 0x00 0x1000 0x00 0xd4282bcc 0x00 0x08 0x00 0xc0b10000 0x00 0x1000>;
			reg-names = "dbi\0atu\0config\0k1x_conf\0phy_ahb\0phy_addr\0conf0_addr\0phy0_addr";
			k1x,pcie-port = <0x00>;
			clocks = <0x1d 0xcb>;
			clock-names = "pcie-clk";
			resets = <0x21 0x59>;
			reset-names = "pcie-reset";
			bus-range = <0x00 0xff>;
			max-link-speed = <0x02>;
			num-lanes = <0x01>;
			num-viewport = <0x08>;
			device_type = "pci";
			#address-cells = <0x03>;
			#size-cells = <0x02>;
			ranges = <0x81000000 0x00 0x80100000 0x00 0x80100000 0x00 0x100000 0x82000000 0x00 0x80200000 0x00 0x80200000 0x00 0xfe00000>;
			interrupts = <0x8d 0x91>;
			interrupt-parent = <0x1e>;
			#interrupt-cells = <0x01>;
			interrupt-map-mask = <0x00 0x00 0x00 0x07>;
			interrupt-map = <0x00 0x00 0x00 0x01 0x2c 0x01 0x00 0x00 0x00 0x02 0x2c 0x02 0x00 0x00 0x00 0x03 0x2c 0x03 0x00 0x00 0x00 0x04 0x2c 0x04>;
			linux,pci-domain = <0x00>;
			status = "disabled";

			interrupt-controller@0 {
				interrupt-controller;
				reg = <0x00 0x00 0x00 0x00 0x00>;
				#address-cells = <0x00>;
				#interrupt-cells = <0x01>;
				phandle = <0x2c>;
			};
		};

		pcie@ca400000 {
			compatible = "k1x,dwc-pcie";
			reg = <0x00 0xca400000 0x00 0x1000 0x00 0xca700000 0x00 0x1ff24 0x00 0x90000000 0x00 0x100000 0x00 0xd4282bd4 0x00 0x08 0x00 0xc0c20000 0x00 0x1000 0x00 0xc0c10000 0x00 0x1000 0x00 0xd4282bcc 0x00 0x08 0x00 0xc0b10000 0x00 0x1000>;
			reg-names = "dbi\0atu\0config\0k1x_conf\0phy_ahb\0phy_addr\0conf0_addr\0phy0_addr";
			k1x,pcie-port = <0x01>;
			clocks = <0x1d 0xcc>;
			clock-names = "pcie-clk";
			resets = <0x21 0x5a>;
			reset-names = "pcie-reset";
			bus-range = <0x00 0xff>;
			max-link-speed = <0x02>;
			num-lanes = <0x02>;
			num-viewport = <0x08>;
			device_type = "pci";
			#address-cells = <0x03>;
			#size-cells = <0x02>;
			ranges = <0x1000000 0x00 0x90100000 0x00 0x90100000 0x00 0x100000 0x2000000 0x00 0x90200000 0x00 0x90200000 0x00 0xfe00000>;
			interrupts = <0x8e 0x92>;
			interrupt-parent = <0x1e>;
			#interrupt-cells = <0x01>;
			interrupt-map-mask = <0x00 0x00 0x00 0x07>;
			interrupt-map = <0x00 0x00 0x00 0x01 0x2d 0x01 0x00 0x00 0x00 0x02 0x2d 0x02 0x00 0x00 0x00 0x03 0x2d 0x03 0x00 0x00 0x00 0x04 0x2d 0x04>;
			linux,pci-domain = <0x01>;
			status = "okay";
			pinctrl-names = "default";
			pinctrl-0 = <0x2e>;

			interrupt-controller@0 {
				interrupt-controller;
				reg = <0x00 0x00 0x00 0x00 0x00>;
				#address-cells = <0x00>;
				#interrupt-cells = <0x01>;
				phandle = <0x2d>;
			};
		};

		pcie@ca800000 {
			compatible = "k1x,dwc-pcie";
			reg = <0x00 0xca800000 0x00 0x1000 0x00 0xcab00000 0x00 0x1ff24 0x00 0xa0000000 0x00 0x100000 0x00 0xd4282bdc 0x00 0x08 0x00 0xc0d20000 0x00 0x1000 0x00 0xc0d10000 0x00 0x1000 0x00 0xd4282bcc 0x00 0x08 0x00 0xc0b10000 0x00 0x1000>;
			reg-names = "dbi\0atu\0config\0k1x_conf\0phy_ahb\0phy_addr\0conf0_addr\0phy0_addr";
			k1x,pcie-port = <0x02>;
			clocks = <0x1d 0xcd>;
			clock-names = "pcie-clk";
			resets = <0x21 0x5b>;
			reset-names = "pcie-reset";
			bus-range = <0x00 0xff>;
			max-link-speed = <0x02>;
			num-lanes = <0x02>;
			num-viewport = <0x08>;
			device_type = "pci";
			#address-cells = <0x03>;
			#size-cells = <0x02>;
			ranges = <0x1000000 0x00 0xa0100000 0x00 0xa0100000 0x00 0x100000 0x2000000 0x00 0xa0200000 0x00 0xa0200000 0x00 0x16000000>;
			interrupts = <0x8f 0x93>;
			interrupt-parent = <0x1e>;
			#interrupt-cells = <0x01>;
			interrupt-map-mask = <0x00 0x00 0x00 0x07>;
			interrupt-map = <0x00 0x00 0x00 0x01 0x2f 0x01 0x00 0x00 0x00 0x02 0x2f 0x02 0x00 0x00 0x00 0x03 0x2f 0x03 0x00 0x00 0x00 0x04 0x2f 0x04>;
			linux,pci-domain = <0x02>;
			status = "disabled";

			interrupt-controller@0 {
				interrupt-controller;
				reg = <0x00 0x00 0x00 0x00 0x00>;
				#address-cells = <0x00>;
				#interrupt-cells = <0x01>;
				phandle = <0x2f>;
			};
		};

		spi@d420c000 {
			compatible = "spacemit,k1x-qspi";
			#address-cells = <0x01>;
			#size-cells = <0x00>;
			reg = <0x00 0xd420c000 0x00 0x1000 0x00 0xb8000000 0x00 0xd00000>;
			reg-names = "qspi-base\0qspi-mmap";
			qspi-sfa1ad = <0xa00000>;
			qspi-sfa2ad = <0xb00000>;
			qspi-sfb1ad = <0xc00000>;
			qspi-sfb2ad = <0xd00000>;
			clocks = <0x1d 0xb8 0x1d 0xb9>;
			clock-names = "qspi_clk\0qspi_bus_clk";
			resets = <0x21 0x4d 0x21 0x4e>;
			reset-names = "qspi_reset\0qspi_bus_reset";
			qspi-pmuap-reg = <0xd4282860>;
			spi-max-frequency = <0x1945ba0>;
			qspi-id = <0x04>;
			status = "okay";
			pinctrl-names = "default";
			pinctrl-0 = <0x30>;

			flash@0 {
				compatible = "jedec,spi-nor";
				reg = <0x00>;
				spi-max-frequency = <0x1945ba0>;
				m25p,fast-read;
				broken-flash-reset;
				status = "okay";
			};
		};

		fuse@f0702800 {
			compatible = "spacemit,k1x-efuse";
			reg = <0x00 0xf0702800 0x00 0x400>;
			resets = <0x21 0x50>;
			reset-names = "aes_reset";
			clocks = <0x1d 0xbb>;
			clock-names = "aes_core";
			status = "okay";
		};

		dpu@c0340000 {
			compatible = "spacemit,dpu";
			reg = <0x00 0xc0340000 0x00 0x2a000 0x00 0xc0440000 0x00 0x2a000>;
			reg-names = "dsi\0hdmi";
			status = "okay";

			port {
				#address-cells = <0x01>;
				#size-cells = <0x00>;

				endpoint@0 {
					reg = <0x00>;
					remote-endpoint = <0x31>;
					phandle = <0x34>;
				};

				endpoint@1 {
					reg = <0x01>;
					remote-endpoint = <0x32>;
					phandle = <0x36>;
				};
			};
		};

		mipi@d421a800 {
			compatible = "spacemit,mipi-dsi";
			reg = <0x00 0xd421a800 0x00 0x200>;
			reg-names = "dsi";
			clocks = <0x1d 0xa8 0x1d 0xa5 0x1d 0xa9 0x1d 0xa6 0x1d 0xa7>;
			clock-names = "pxclk\0mclk\0hclk\0escclk\0bitclk";
			resets = <0x21 0x40 0x21 0x44 0x21 0x3e 0x21 0x3d>;
			reset-names = "dsi_reset\0mclk_reset\0esc_reset\0lcd_reset";
			power-domains = <0x33 0x02>;
			status = "disabled";

			ports {

				port {
					#address-cells = <0x01>;
					#size-cells = <0x00>;

					endpoint@0 {
						reg = <0x00>;
						remote-endpoint = <0x34>;
						phandle = <0x31>;
					};
				};
			};
		};

		panel {
			compatible = "spacemit,panel";
			status = "disabled";
			dcp-gpios = <0x2a 0x52 0x00>;
			dcn-gpios = <0x2a 0x53 0x00>;
			bl-gpios = <0x2a 0x2c 0x00>;
			reset-gpios = <0x2a 0x51 0x00>;
		};

		hdmi@c0400500 {
			compatible = "spacemit,hdmi";
			reg = <0x00 0xc0400500 0x00 0x200>;
			reg-names = "hdmi";
			clocks = <0x1d 0xc1>;
			clock-names = "hmclk";
			resets = <0x21 0x58>;
			reset-names = "hdmi_reset";
			power-domains = <0x33 0x06>;
			status = "okay";
			pinctrl-names = "default";
			pinctrl-0 = <0x35>;

			ports {

				port {
					#address-cells = <0x01>;
					#size-cells = <0x00>;

					endpoint@0 {
						reg = <0x00>;
						remote-endpoint = <0x36>;
						phandle = <0x32>;
					};
				};
			};
		};
	};

	binman {
		multiple-images;

		itb {
			filename = "u-boot.itb";

			fit {
				description = "Configuration to load U-Boot";
				#address-cells = <0x02>;
				fit,fdt-list = "of-list";

				images {

					uboot {
						description = "U-Boot";
						type = "standalone";
						os = "U-Boot";
						arch = "riscv";
						compression = "none";
						load = <0x200000>;

						blob-ext {
							filename = "u-boot-nodtb.bin";
						};
					};

					@fdt-SEQ {
						description = "NAME";
						type = "flat_dt";
						compression = "none";
					};
				};

				configurations {
					default = "conf-1";

					@conf-SEQ {
						description = "U-boot FIT config";
						loadables = "uboot";
						fdt = "fdt-SEQ";
					};
				};
			};
		};
	};

	pmu {
		compatible = "riscv,pmu";
		riscv,event-to-mhpmevent = <0x05 0x00 0x01 0x06 0x00 0x02 0x08 0x00 0x03 0x09 0x00 0x04 0x10000 0x00 0x06 0x10001 0x00 0x05 0x10002 0x00 0x0a 0x10003 0x00 0x09 0x10008 0x00 0x0c 0x10009 0x00 0x0b 0x1000c 0x00 0x0e 0x1000d 0x00 0x0d 0x10019 0x00 0x15 0x1001b 0x00 0x19 0x10021 0x00 0x1b>;
		riscv,event-to-mhpmcounters = <0x05 0x06 0x7fff8 0x08 0x09 0x7fff8 0x10000 0x10003 0x7fff8 0x10008 0x10009 0x7fff8 0x1000c 0x1000d 0x7fff8 0x10019 0x10019 0x7fff8 0x1001b 0x1001b 0x7fff8 0x10021 0x10021 0x7fff8>;
		riscv,raw-event-to-mhpmcounters = <0x00 0x00 0xffffffff 0xffffff00 0x7fff8>;
	};

	memory@0 {
		device_type = "memory";
		reg = <0x00 0x00 0x00 0x40000000>;
	};

	usb3hub {
		compatible = "spacemit,usb-hub";
		hub-gpios = <0x2a 0x7b 0x00 0x2a 0x7c 0x00>;
		vbus-gpios = <0x2a 0x61 0x00>;
		regulator-force-boot-off;
		vbus_delay_ms = <0xfa>;
		status = "okay";
		phandle = <0x25>;
	};
};
